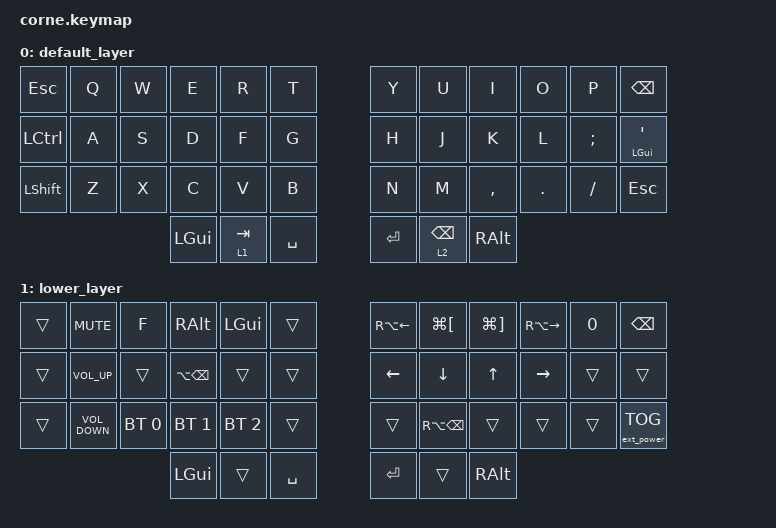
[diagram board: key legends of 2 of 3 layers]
/*
 * Copyright (c) 2020 The ZMK Contributors
 *
 * SPDX-License-Identifier: MIT
 */

#include <behaviors.dtsi>
#include <dt-bindings/zmk/bt.h>
#include <dt-bindings/zmk/ext_power.h>
#include <dt-bindings/zmk/keys.h>

/ {
    keymap {
        compatible = "zmk,keymap";

        default_layer {
            // -----------------------------------------------------------------------------------------
            // |  ESC |  Q  |  W  |  E  |  R  |  T  |   |  Y  |  U   |  I  |  O  |  P  | BKSP |
            // | CTRL |  A  |  S  |  D  |  F  |  G  |   |  H  |  J   |  K  |  L  |  ;  |  MT(LGUI, ')   |
            // | SHFT |  Z  |  X  |  C  |  V  |  B  |   |  N  |  M   |  ,  |  .  |  /  | ESC  |
            //                    | GUI | LT(1, TAB) | SPC |   | ENT | LT(2, BSPC)  | ALT |

            bindings = <
  &kp ESC  &kp Q  &kp W     &kp E      &kp R      &kp T      &kp Y       &kp U      &kp I    &kp O     &kp P      &kp BSPC
&kp LCTRL  &kp A  &kp S     &kp D      &kp F      &kp G      &kp H       &kp J      &kp K    &kp L  &kp SEMI  &mt LGUI SQT
&kp LSHFT  &kp Z  &kp X     &kp C      &kp V      &kp B      &kp N       &kp M  &kp COMMA  &kp DOT  &kp FSLH       &kp ESC
                         &kp LGUI  &lt 1 TAB  &kp SPACE    &kp RET  &lt 2 BSPC   &kp RALT
            >;
        };

        lower_layer {
            //                        -----------------------------------------------------------------------------------------
            //                        |      | VX  |  F  | ALT        | LGUI |     |   | XRALT(<)  |  LGUI([)   |  LGUI(])  | XRALT(>) |  0  | BKSP |
            //                        |      | V+  |     | RALT(BSPC) |      |     |   | LFT       |    DWN     |    UP     | RGT      |     |      |
            //                        |      | V-  | BT0 | BT1        | BT2  |     |   |           | RALT(BSPC) |           |          |     |      |
            //                                           | GUI        |      | SPC |   | ENT       |            |   ALT     |

            bindings = <
&trans         &kp C_MUTE         &kp F           &kp RALT      &kp LGUI     &trans    &kp RA(LEFT)  &kp LG(LBKT)  &kp LG(RBKT)  &kp RA(RIGHT)  &kp N0           &kp BSPC
&trans       &kp C_VOL_UP        &trans  &kp LA(BACKSPACE)        &trans     &trans        &kp LEFT      &kp DOWN        &kp UP      &kp RIGHT  &trans             &trans
&trans  &kp C_VOLUME_DOWN  &bt BT_SEL 0       &bt BT_SEL 1  &bt BT_SEL 2     &trans          &trans  &kp RA(BSPC)        &trans         &trans  &trans  &ext_power EP_TOG
                                                  &kp LGUI        &trans  &kp SPACE         &kp RET        &trans      &kp RALT
            >;
        };

        raise_layer {
            //                     -----------------------------------------------------------------------------------------
            //                     | & |  !  |  @  |  {  |  }  |  *  |   |  %  |  1  |  2  |  3  |  0  |  `  |
            //                     | " |  ^  |  $  |  (  |  )  |  -  |   |     |  4  |  5  |  6  |  =  |  ~  |
            //                     | ' |  _  |  #  |  [  |  ]  |  +  |   | "|" |  7  |  8  |  9  |  <  |  >  |
            //                                       GUI |     | SPC |   | ENT |     | ALT |

            bindings = <
&kp AMPS   &kp EXCL    &kp AT  &kp LBRC   &kp RBRC  &kp ASTRK    &kp PRCNT    &kp N1  &kp N2  &kp N3     &kp N0  &kp GRAVE
 &kp DQT  &kp CARET  &kp DLLR  &kp LPAR   &kp RPAR  &kp MINUS       &trans    &kp N4  &kp N5  &kp N6  &kp EQUAL  &kp TILDE
 &kp SQT  &kp UNDER  &kp HASH  &kp LBKT   &kp RBKT   &kp PLUS     &kp PIPE    &kp N7  &kp N8  &kp N9     &kp LT     &kp GT
                                 &trans  &kp SPACE    &kp RET       &trans  &kp RALT
            >;
        };
    };
};
